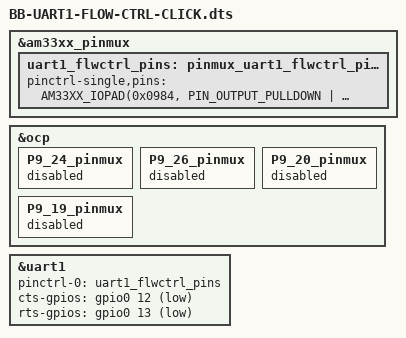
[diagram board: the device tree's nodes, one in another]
/* Copyright (C) 2017 Robert Nelson <robertcnelson@gmail.com>
 *
 * This program is free software; you can redistribute it and/or modify
 * it under the terms of the GNU General Public License version 2 as
 * published by the Free Software Foundation.
 */

/dts-v1/;
/plugin/;

#include <dt-bindings/board/am335x-bbw-bbb-base.h>
#include <dt-bindings/gpio/gpio.h>
#include <dt-bindings/pinctrl/am33xx.h>

/ {
	fragment@0 {
		target = <&am33xx_pinmux>;
		__overlay__ {
			uart1_flwctrl_pins: pinmux_uart1_flwctrl_pins {
				pinctrl-single,pins = <
					AM33XX_IOPAD(0x0984, PIN_OUTPUT_PULLDOWN | MUX_MODE0)
					AM33XX_IOPAD(0x0980, PIN_INPUT_PULLUP	 | MUX_MODE0)
					AM33XX_IOPAD(0x0978, PIN_INPUT_PULLUP	 | MUX_MODE0)
					AM33XX_IOPAD(0x097C, PIN_OUTPUT_PULLDOWN | MUX_MODE0)
				>;
			};

		};
	};

	fragment@1 {
		target = <&ocp>;
		__overlay__ {

			P9_24_pinmux {
				status = "disabled";
			};
			P9_26_pinmux {
				status = "disabled";
			};
			P9_20_pinmux {
				status = "disabled";
			};
			P9_19_pinmux {
				status = "disabled";
			};
		};
	};

	fragment@2 {
		target = <&uart1>;
		__overlay__ {

			status = "okay";
			pinctrl-names = "default";
			pinctrl-0 = <&uart1_flwctrl_pins>;
			
			#address-cells = <1>;
			#size-cells = <0>;
			
			cts-gpios = <&gpio0 12 GPIO_ACTIVE_LOW>;
			rts-gpios = <&gpio0 13 GPIO_ACTIVE_LOW>;

		};
	};
};
